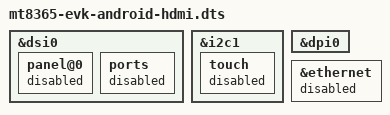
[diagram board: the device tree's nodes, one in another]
// SPDX-License-Identifier: GPL-2.0
/*
 * Copyright (c) 2025 BayLibre, SAS.
 * Author: Julien Masson <jmasson@baylibre.com>
 */

/dts-v1/;
/plugin/;

#include "mt8365-evk-android.dtsi"

&dsi0 {
        panel@0 {
                status = "disabled";
        };
        ports {
                status = "disabled";
        };
};

&i2c1 {
        touch {
                status = "disabled";
        };
};

&dpi0 {
	status = "okay";
};

&ethernet {
	/*
	 * Ethernet and HDMI (DPI0) are sharing pins.
	 * Only one can be enabled at a time and require the physical switch
	 * SW2101 to be set on the desired position
	 */
	status = "disabled";
};
